# ADSP-SC83xW_HPC register map
Vendor: Analog Devices; Series: ADSP-SC83xW_HPC; File version: 3.0.3.517
CPU: 
Registers are 32-bit, read-write, reset 0x0 unless marked. A register's access mark holds for its fields unless they carry their own. Offsets are from the block's base; [hi:lo] are bit positions; {n}, {i} and the like mark numbered series; 'fields as' and 'values as' point back to an identical list.

## DAPROM0
Base 0x31100000
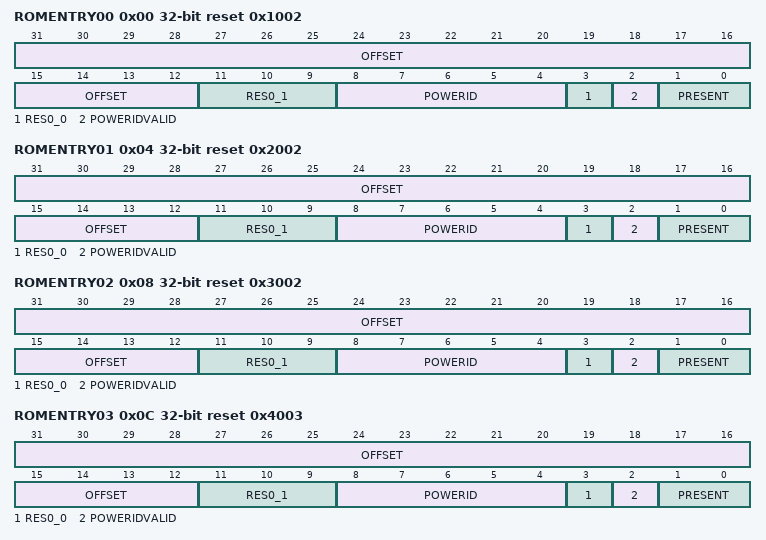
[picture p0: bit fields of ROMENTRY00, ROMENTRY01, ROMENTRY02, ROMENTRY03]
0x00 ROMENTRY00 reset 0x1002 — ROM Entries Register 0.
  [31:12] OFFSET ro, [11:9] RES0_1 ro, [8:4] POWERID ro, [3] RES0_0 ro, [2] POWERIDVALID ro, [1:0] PRESENT ro
0x04 ROMENTRY01 reset 0x2002 — ROM Entries Register 1.
  fields as ROMENTRY00
0x08 ROMENTRY02 reset 0x3002 — ROM Entries Register 2.
  fields as ROMENTRY00
0x0C ROMENTRY03 reset 0x4003 — ROM Entries Register 3.
  fields as ROMENTRY00
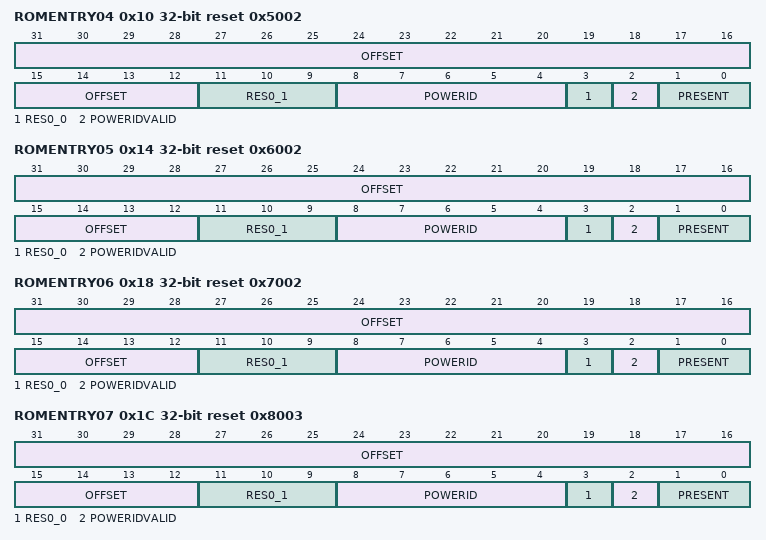
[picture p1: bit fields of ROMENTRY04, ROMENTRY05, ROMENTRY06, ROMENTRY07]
0x10 ROMENTRY04 reset 0x5002 — ROM Entries Register 4.
  fields as ROMENTRY00
0x14 ROMENTRY05 reset 0x6002 — ROM Entries Register 5.
  fields as ROMENTRY00
0x18 ROMENTRY06 reset 0x7002 — ROM Entries Register 6.
  fields as ROMENTRY00
0x1C ROMENTRY07 reset 0x8003 — ROM Entries Register 7.
  fields as ROMENTRY00
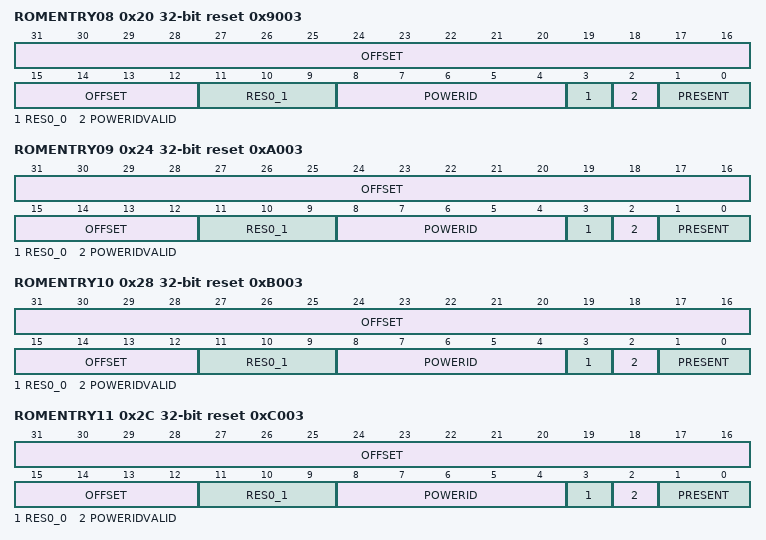
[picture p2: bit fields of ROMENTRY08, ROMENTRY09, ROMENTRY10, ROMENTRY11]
0x20 ROMENTRY08 reset 0x9003 — ROM Entries Register 8.
  fields as ROMENTRY00
0x24 ROMENTRY09 reset 0xA003 — ROM Entries Register 9.
  fields as ROMENTRY00
0x28 ROMENTRY10 reset 0xB003 — ROM Entries Register 10.
  fields as ROMENTRY00
0x2C ROMENTRY11 reset 0xC003 — ROM Entries Register 11.
  fields as ROMENTRY00
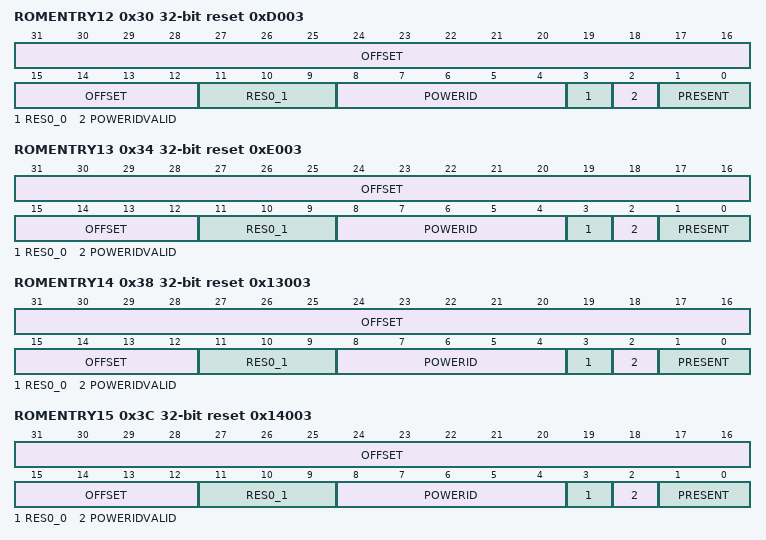
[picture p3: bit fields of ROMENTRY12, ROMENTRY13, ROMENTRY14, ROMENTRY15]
0x30 ROMENTRY12 reset 0xD003 — ROM Entries Register 12.
  fields as ROMENTRY00
0x34 ROMENTRY13 reset 0xE003 — ROM Entries Register 13.
  fields as ROMENTRY00
0x38 ROMENTRY14 reset 0x13003 — ROM Entries Register 14.
  fields as ROMENTRY00
0x3C ROMENTRY15 reset 0x14003 — ROM Entries Register 15.
  fields as ROMENTRY00
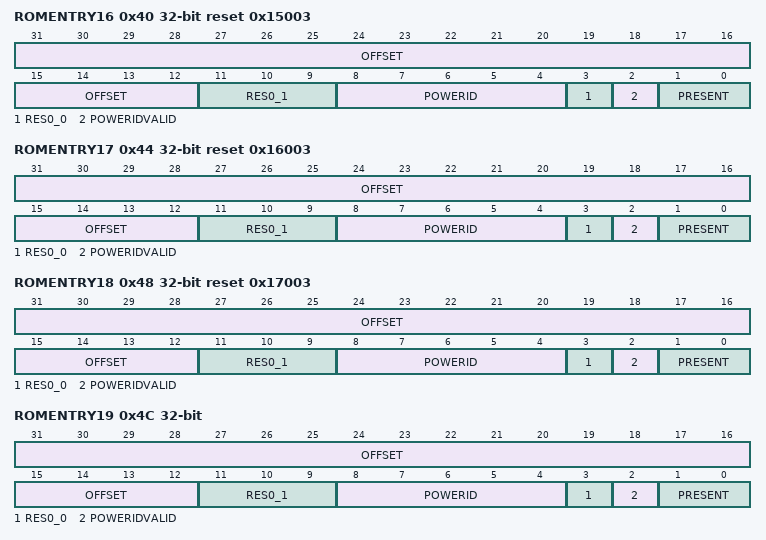
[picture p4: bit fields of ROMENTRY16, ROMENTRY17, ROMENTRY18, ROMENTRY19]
0x40 ROMENTRY16 reset 0x15003 — ROM Entries Register 16.
  fields as ROMENTRY00
0x44 ROMENTRY17 reset 0x16003 — ROM Entries Register 17.
  fields as ROMENTRY00
0x48 ROMENTRY18 reset 0x17003 — ROM Entries Register 18.
  fields as ROMENTRY00
0x4C ROMENTRY19 — ROM Entries Register 19.
  fields as ROMENTRY00
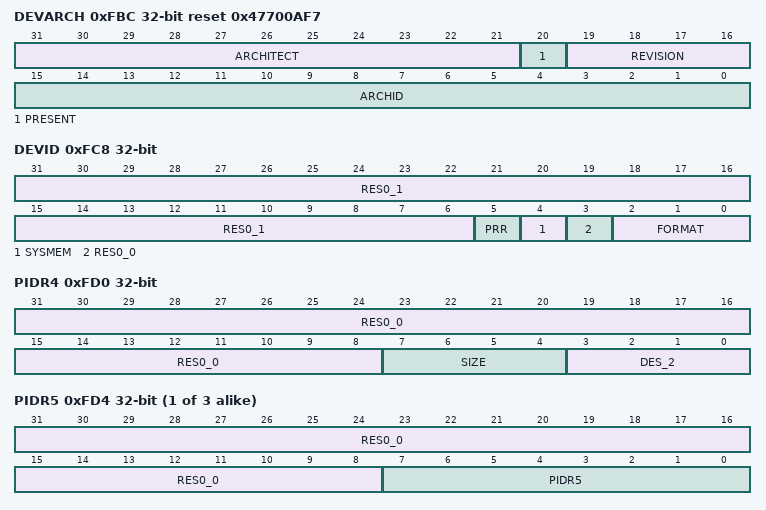
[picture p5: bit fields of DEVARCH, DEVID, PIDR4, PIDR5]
0xFBC DEVARCH reset 0x47700AF7 — Device Architecture Register.
  [31:21] ARCHITECT ro, [20] PRESENT ro, [19:16] REVISION ro, [15:0] ARCHID ro
0xFC8 DEVID — Device Configuration Register.
  [31:6] RES0_1 ro, [5] PRR ro, [4] SYSMEM ro, [3] RES0_0 ro, [2:0] FORMAT ro
0xFD0 PIDR4 — Peripheral Identification Register 4.
  [31:8] RES0_0 ro, [7:4] SIZE ro, [3:0] DES_2 ro
{0xFC0+4i} PIDR{i} (i=5..7) — Peripheral Identification Register {i}.
  [31:8] RES0_0 ro, [7:0] PIDR{i} ro
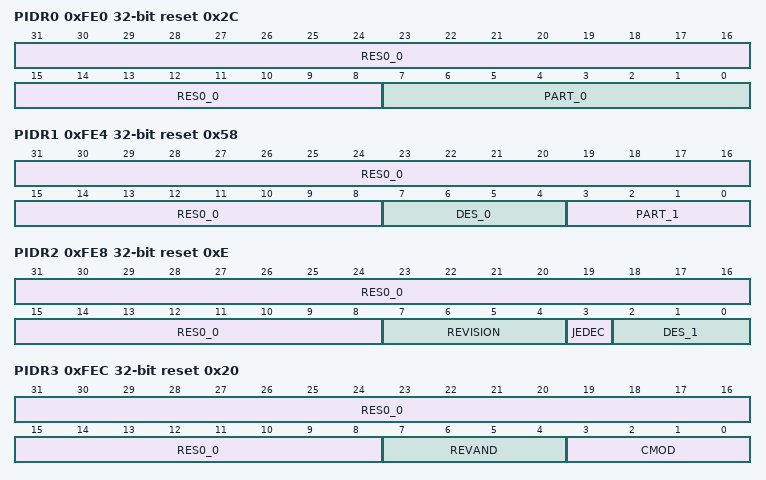
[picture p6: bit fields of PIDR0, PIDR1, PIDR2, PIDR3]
0xFE0 PIDR0 reset 0x2C — Peripheral Identification Register 0.
  [31:8] RES0_0 ro, [7:0] PART_0 ro
0xFE4 PIDR1 reset 0x58 — Peripheral Identification Register 1.
  [31:8] RES0_0 ro, [7:4] DES_0 ro, [3:0] PART_1 ro
0xFE8 PIDR2 reset 0xE — Peripheral Identification Register 2.
  [31:8] RES0_0 ro, [7:4] REVISION ro, [3] JEDEC ro, [2:0] DES_1 ro
0xFEC PIDR3 reset 0x20 — Peripheral Identification Register 3.
  [31:8] RES0_0 ro, [7:4] REVAND ro, [3:0] CMOD ro
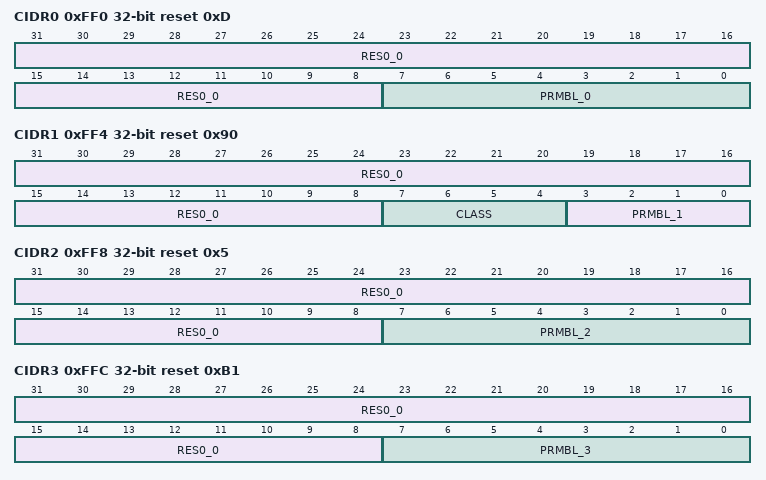
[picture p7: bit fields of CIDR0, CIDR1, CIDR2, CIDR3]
0xFF0 CIDR0 reset 0xD — Component Identification Register 0.
  [31:8] RES0_0 ro, [7:0] PRMBL_0 ro
0xFF4 CIDR1 reset 0x90 — Component Identification Register 1.
  [31:8] RES0_0 ro, [7:4] CLASS ro, [3:0] PRMBL_1 ro
0xFF8 CIDR2 reset 0x5 — Component Identification Register 2.
  [31:8] RES0_0 ro, [7:0] PRMBL_2 ro
0xFFC CIDR3 reset 0xB1 — Component Identification Register 3.
  [31:8] RES0_0 ro, [7:0] PRMBL_3 ro

## Performance_Monitor_Registers
Base 0x31114000
0x1000 PMG
  [0] PMEN range 0x00000000..0x00000001
0x1010 INTPC
  [31:0] INTPC ro
{0x1080+4i} PM{i} (i=0..7)
  [31:0] PM{i} range 0x00000000..0xFFFFFFFF
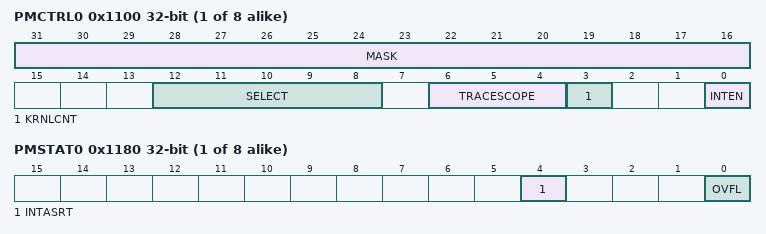
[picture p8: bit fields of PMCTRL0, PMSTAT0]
{0x1100+4i} PMCTRL{i} (i=0..7)
  [31:16] MASK range 0x00000000..0x0000FFFF, [12:8] SELECT range 0x00000000..0x0000001F, [6:4] TRACESCOPE range 0x00000000..0x00000007, [3] KRNLCNT range 0x00000000..0x00000001, [0] INTEN range 0x00000000..0x00000001
{0x1180+4i} PMSTAT{i} (i=0..7)
  [4] INTASRT range 0x00000000..0x00000001, [0] OVFL range 0x00000000..0x00000001

## Miscellaneous_Registers
Base 0x31114000
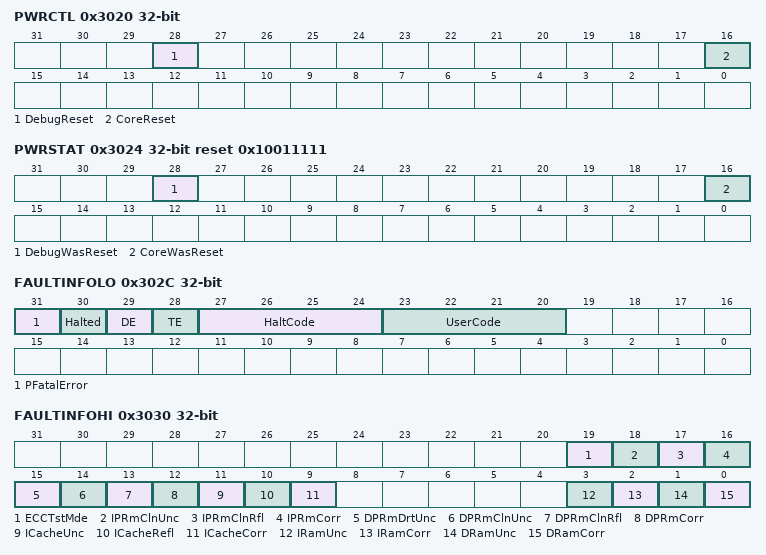
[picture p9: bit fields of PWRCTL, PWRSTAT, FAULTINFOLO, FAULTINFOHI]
0x3020 PWRCTL
  [28] DebugReset range 0x00000000..0x00000001, [16] CoreReset range 0x00000000..0x00000001
0x3024 PWRSTAT reset 0x10011111
  [28] DebugWasReset range 0x00000000..0x00000001, [16] CoreWasReset range 0x00000000..0x00000001
0x3028 ERISTAT
  [0] WRISUC ro
0x302C FAULTINFOLO
  [31] PFatalError ro, [30] Halted ro, [29] DE ro, [28] TE ro, [27:24] HaltCode ro, [23:20] UserCode range 0x00000000..0x0000000F
0x3030 FAULTINFOHI
  [19] ECCTstMde ro, [18] IPRmClnUnc ro, [17] IPRmClnRfl ro, [16] IPRmCorr ro, [15] DPRmDrtUnc ro, [14] DPRmClnUnc ro, [13] DPRmClnRfl ro, [12] DPRmCorr ro, [11] ICacheUnc ro, [10] ICacheRefl ro, [9] ICacheCorr ro, [3] IRamUnc ro, [2] IRamCorr ro, [1] DRamUnc ro, [0] DRamCorr ro
